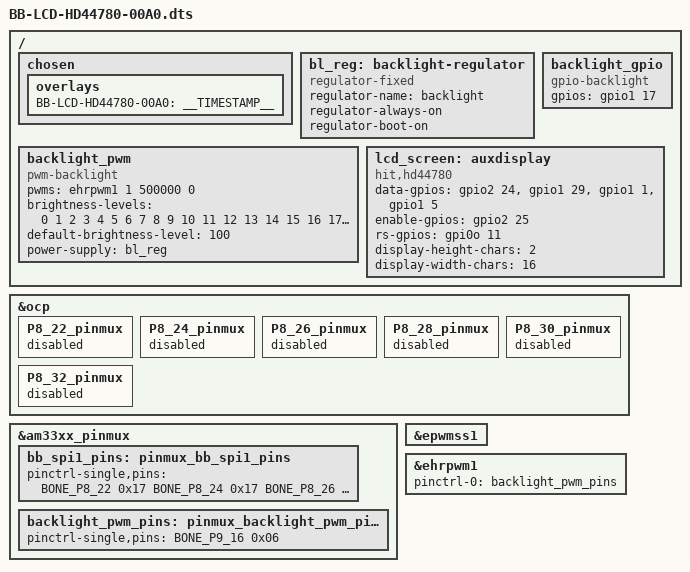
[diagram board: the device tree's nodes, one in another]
/*
 * Copyright (C) 2013 CircuitCo
 * Copyright (C) 2018 Drew Fustini <drew@beagleboard.org>
 * Copyright (C) 2020 Mark A. Yoder <mark.a.yoder@beagleboard.org>
 *
 * Basic 16x2 Character LCD with HD4470 driver
 *
 * LICENSE:
 * --------
 * This program is free software; you can redistribute it and/or modify
 * it under the terms of the GNU General Public License version 2 as
 * published by the Free Software Foundation.
 *
 * DOCUMENTATION:
 * --------------
 * This file was copied from src/arm/BB-SPIDEV1-00A0.dts and modified
 * by Drew Fustini based on an exmample from David Lechner.
 * Later modified by Mark A. Yoder for the 2.4" LCD.
 * And even laterd modified for a 2x16 character display.
 *
 * This is the SparkFun 2x16 LCD:
 * Basic 16x2 Character LCD
 *
 * It should be connected to BeagleBone:
 *
 *	D4	P8_28
 *	D5	P8_26
 *	D6	P8_24
 *	D8	P8_22
 *	E	P8_32
 *	RS	P8_34
 *
 * Tested with 4.19.59-ti-r26 kernel on Debian 10.1 image
 *
 */

#include <dt-bindings/gpio/gpio.h>
#include <dt-bindings/pinctrl/am33xx.h>
#include <dt-bindings/board/am335x-bbw-bbb-base.h>

/dts-v1/;
/plugin/;

/ {
	/*
	 * Helper to show loaded overlays under: /proc/device-tree/chosen/overlays/
	 */
	fragment@0 {
		target-path="/";
		__overlay__ {

			chosen {
				overlays {
					BB-LCD-HD44780-00A0 = __TIMESTAMP__;
				};
			};
		};
	};

	/*
	 * Free up the pins used by the cape from the pinmux helpers.
	 */
	fragment@1 {
		target = <&ocp>;
		__overlay__ {
			P8_22_pinmux { status = "disabled"; };	/* D7 */
			P8_24_pinmux { status = "disabled"; };	/* D6 */
			P8_26_pinmux { status = "disabled"; };	/* D5 */
			P8_28_pinmux { status = "disabled"; };	/* D4 */
			
			P8_30_pinmux { status = "disabled"; };  /* E */
			P8_32_pinmux { status = "disabled"; };	/* RS */
		};
	};

	fragment@2 {
		target = <&am33xx_pinmux>;
		__overlay__ {
			/* default state has all gpios released and mode set to uart1 */
			/* See page 1446 of am35xx TRM */
			bb_spi1_pins: pinmux_bb_spi1_pins {
				pinctrl-single,pins = <
					BONE_P8_22 0x17	/* GPIO    OUTPUT_PULLUP | MODE7 */
					BONE_P8_24 0x17	/* GPIO    OUTPUT_PULLUP | MODE7 */
					BONE_P8_26 0x17	/* GPIO    OUTPUT_PULLUP | MODE7 */
					BONE_P8_28 0x17	/* GPIO    OUTPUT_PULLUP | MODE7 */
					
					BONE_P8_30 0x17	/* GPIO    OUTPUT_PULLUP | MODE7 */
					BONE_P8_32 0x17	/* GPIO    OUTPUT_PULLUP | MODE7 */
				>;
			};

			backlight_pwm_pins: pinmux_backlight_pwm_pins {
				pinctrl-single,pins = <
					BONE_P9_16 0x06 /* gpmc_a2.ehrpwm1b, OMAP_MUX_MODE6 | AM33XX_PIN_OUTPUT */
				>;
			};  /* gpmc_a2.ehrpwm1b */
		};
	};

	fragment@3 {
		target = <&epwmss1>;
		__overlay__ {
			status = "okay";
		};
	};

	fragment@4 {
		target = <&ehrpwm1>;
		__overlay__ {
			pinctrl-names = "default";
			pinctrl-0 = <&backlight_pwm_pins>;
			status = "okay";
		};
	};

	fragment@5 {
		target-path = "/";
		__overlay__ {

			bl_reg: backlight-regulator {
				compatible = "regulator-fixed";
				regulator-name = "backlight";
				regulator-always-on;
				regulator-boot-on;
			};

			/* backlight is optional */
			backlight_gpio: backlight_gpio {
				compatible = "gpio-backlight";
				gpios = <&gpio1 17 GPIO_ACTIVE_HIGH>;
				// connect lcd lite pin to P9.23 which is gpio1[17]
				// refer to https://elinux.org/Beagleboard:Cape_Expansion_Headers
			};

			/*
			 * Turn the PWM backlight on by setting bl_power to 0:
			 * echo 0 > /sys/class/backlight/backlight_pwm/bl_power
			 */
			backlight_pwm: backlight_pwm {
				// P9.16 <--> lite (pwm-backlight EHRPWM1B)
				status = "okay";
				compatible = "pwm-backlight";
				pwms = <&ehrpwm1 1 500000 0>;	// First digit: 0 for A side of pwm, 1 for B side
												// 500000 is the PWM period in ns
												// https://git.kernel.org/pub/scm/linux/kernel/git/torvalds/linux.git/tree/Documentation/devicetree/bindings/pwm/pwm.txt
				brightness-levels = <
					0  1  2  3  4  5  6  7  8  9
					10 11 12 13 14 15 16 17 18 19
					20 21 22 23 24 25 26 27 28 29
					30 31 32 33 34 35 36 37 38 39
					40 41 42 43 44 45 46 47 48 49
					50 51 52 53 54 55 56 57 58 59
					60 61 62 63 64 65 66 67 68 69
					70 71 72 73 74 75 76 77 78 79
					80 81 82 83 84 85 86 87 88 89
					90 91 92 93 94 95 96 97 98 99
					100
				>;
				default-brightness-level = <100>;
				power-supply = <&bl_reg>;
			};
		};
	};

// From: https://github.com/raspberrypi/linux/blob/rpi-5.4.y/arch/arm/boot/dts/overlays/hd44780-lcd-overlay.dts
	fragment@6 {
        target-path = "/";
        __overlay__ {
            lcd_screen: auxdisplay {
                compatible = "hit,hd44780";

                data-gpios = <&gpio2 24 0>,		//	P8_28
                             <&gpio1 29 0>,		//	P8_26
                             <&gpio1  1 0>,		//	P8_24
                             <&gpio1  5 0>;		//	P8_22
                enable-gpios = <&gpio2 25 0>;	//	P8_30
                rs-gpios = <&gpi0o 11 0>;		//	P8_32

                display-height-chars = <2>;
                display-width-chars = <16>;
            };

        };
    };
};
